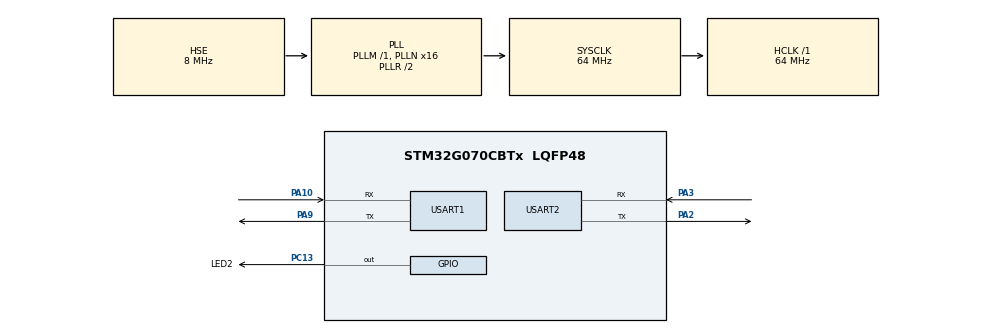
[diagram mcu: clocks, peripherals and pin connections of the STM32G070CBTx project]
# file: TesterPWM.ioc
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Mcu.Family=STM32G0
Mcu.Name=STM32G070CBTx
Mcu.Package=LQFP48
NVIC.USART1_IRQn=true\:0\:0\:false\:false\:true\:true\:true\:true
NVIC.USART2_IRQn=true\:0\:0\:false\:false\:true\:true\:true\:true
PA10.Mode=Asynchronous
PA10.Signal=USART1_RX
PA13.Mode=Serial_Wire
PA13.Signal=SYS_SWDIO
PA14-BOOT0.Mode=Serial_Wire
PA14-BOOT0.Signal=SYS_SWCLK
PA2.Mode=Asynchronous
PA2.Signal=USART2_TX
PA3.Mode=Asynchronous
PA3.Signal=USART2_RX
PA9.Mode=Asynchronous
PA9.Signal=USART1_TX
PC13.GPIO_Label=LED2
PC13.Signal=GPIO_Output
PF0-OSC_IN\ (PF0).Mode=HSE-External-Clock-Source
PF0-OSC_IN\ (PF0).Signal=RCC_OSC_IN
ProjectManager.HeapSize=0x200
ProjectManager.StackSize=0x400
ProjectManager.TargetToolchain=STM32CubeIDE
RCC.ADCFreq_Value=64000000
RCC.AHBFreq_Value=64000000
RCC.CortexFreq_Value=64000000
RCC.EXTERNAL_CLOCK_VALUE=48000
RCC.HCLKFreq_Value=64000000
RCC.HSE_VALUE=8000000
RCC.HSI_VALUE=16000000
RCC.LSE_VALUE=32768
RCC.PLLN=16
RCC.PLLSourceVirtual=RCC_PLLSOURCE_HSE
RCC.SYSCLKFreq_VALUE=64000000
RCC.SYSCLKSource=RCC_SYSCLKSOURCE_PLLCLK
RCC.VCOOutputFreq_Value=128000000
USART1.VirtualMode-Asynchronous=VM_ASYNC
USART2.VirtualMode-Asynchronous=VM_ASYNC
board=custom

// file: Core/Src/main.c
/* USER CODE BEGIN Header */
/**
  ******************************************************************************
  * @file           : main.c
  * @brief          : Main program body
  ******************************************************************************
  * @attention
  *
  * Copyright (c) 2023 STMicroelectronics.
  * All rights reserved.
  *
  * This software is licensed under terms that can be found in the LICENSE file
  * in the root directory of this software component.
  * If no LICENSE file comes with this software, it is provided AS-IS.
  *
  ******************************************************************************
  */
/* USER CODE END Header */
#include "main.h"
#include "usart.h"
#include "gpio.h"

void SystemClock_Config(void);

int main(void)
{

  /* MCU Configuration--------------------------------------------------------*/

  /* Reset of all peripherals, Initializes the Flash interface and the Systick. */
  HAL_Init();

  /* Configure the system clock */
  SystemClock_Config();

  /* Initialize all configured peripherals */
  MX_GPIO_Init();
  MX_USART1_UART_Init();
  MX_USART2_UART_Init();
  /* USER CODE BEGIN 2 */
  // startup message
  HAL_UART_Transmit(&huart2, "Hi!", 3, 0xFFF);
//  HAL_UART_Receive_IT(&huart1, (uint8_t*)buff, 15);
  /* USER CODE END 2 */

  /* Infinite loop */
  /* USER CODE BEGIN WHILE */
  while (1)
  {
	  HAL_GPIO_WritePin(GPIOC, GPIO_PIN_13, GPIO_PIN_RESET);
	  HAL_Delay(500);
	  HAL_GPIO_WritePin(GPIOC, GPIO_PIN_13, GPIO_PIN_SET);
	  HAL_Delay(500);
    /* USER CODE END WHILE */

  }
}

void SystemClock_Config(void)
{
  RCC_OscInitTypeDef RCC_OscInitStruct = {0};
  RCC_ClkInitTypeDef RCC_ClkInitStruct = {0};

  /** Configure the main internal regulator output voltage
  */
  HAL_PWREx_ControlVoltageScaling(PWR_REGULATOR_VOLTAGE_SCALE1);

  /** Initializes the RCC Oscillators according to the specified parameters
  * in the RCC_OscInitTypeDef structure.
  */
  RCC_OscInitStruct.OscillatorType = RCC_OSCILLATORTYPE_HSE;
  RCC_OscInitStruct.HSEState = RCC_HSE_BYPASS;
  RCC_OscInitStruct.PLL.PLLState = RCC_PLL_ON;
  RCC_OscInitStruct.PLL.PLLSource = RCC_PLLSOURCE_HSE;
  RCC_OscInitStruct.PLL.PLLM = RCC_PLLM_DIV1;
  RCC_OscInitStruct.PLL.PLLN = 16;
  RCC_OscInitStruct.PLL.PLLP = RCC_PLLP_DIV2;
  RCC_OscInitStruct.PLL.PLLR = RCC_PLLR_DIV2;
  if (HAL_RCC_OscConfig(&RCC_OscInitStruct) != HAL_OK)
  {
    Error_Handler();
  }

  /** Initializes the CPU, AHB and APB buses clocks
  */
  RCC_ClkInitStruct.ClockType = RCC_CLOCKTYPE_HCLK|RCC_CLOCKTYPE_SYSCLK
                              |RCC_CLOCKTYPE_PCLK1;
  RCC_ClkInitStruct.SYSCLKSource = RCC_SYSCLKSOURCE_PLLCLK;
  RCC_ClkInitStruct.AHBCLKDivider = RCC_SYSCLK_DIV1;
  RCC_ClkInitStruct.APB1CLKDivider = RCC_HCLK_DIV1;

  if (HAL_RCC_ClockConfig(&RCC_ClkInitStruct, FLASH_LATENCY_2) != HAL_OK)
  {
    Error_Handler();
  }
}

void Error_Handler(void)
{
  __disable_irq();
  while (1)
  {
  }
}
